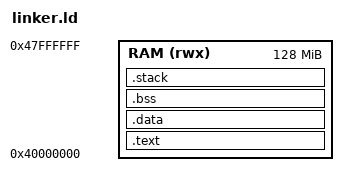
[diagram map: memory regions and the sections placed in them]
MEMORY
{
    RAM (rwx) : ORIGIN = 0x40000000, LENGTH = 128M
}

SECTIONS
{
    .text :
    {
        KEEP(*(.vectors))
        *(.text*)
        *(.rodata*)
        . = ALIGN(4);
        _etext = .;
    } > RAM

    .data :
    {
        _sdata = .;
        *(.data*)
        . = ALIGN(4);
        _edata = .;
    } > RAM

    .bss :
    {
        _sbss = .;
        *(.bss*)
        *(COMMON)
        . = ALIGN(4);
        _ebss = .;
    } > RAM

    .stack (NOLOAD) :
    {
        . = ALIGN(8);
        . += 0x4000;            /* 16KB stack */
        _stack_top = .;
    } > RAM
}
